# R7FA6E2BB register map
Vendor: Renesas Electronics Corporation; Series: RA6; File version: 1.30.00
CPU: CM33 r0p4, little endian, MPU, FPU, VTOR, 4 interrupt priority bits, 96 interrupts
Registers are 32-bit, read-write, reset 0x0 unless marked. A register's access mark holds for its fields unless they carry their own. Offsets are from the block's base; [hi:lo] are bit positions; 'fields as' and 'values as' point back to an identical list.

## POEG — Port Output Enable Module for GPT
Base 0x4008A000
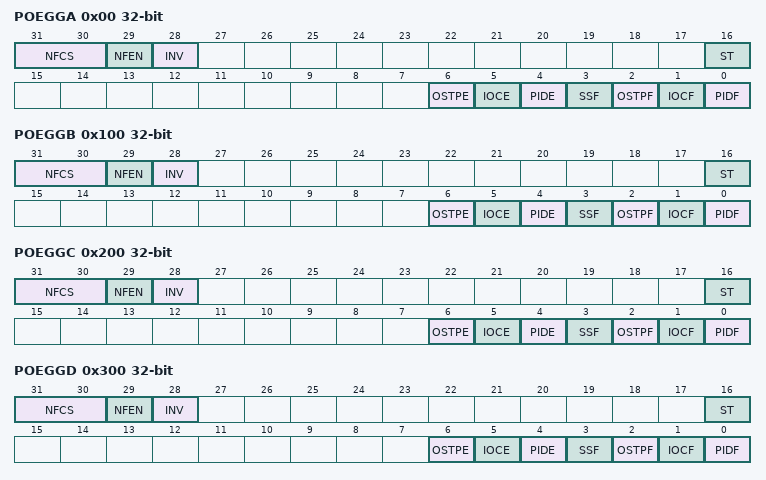
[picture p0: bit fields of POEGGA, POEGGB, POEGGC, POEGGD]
0x00 POEGGA — POEG Group A Setting Register
  [31:30] NFCS — Noise Filter Clock Select
  [29] NFEN — Noise Filter Enable
  [28] INV — GTETRGn Input Reverse
  [16] ST ro — GTETRGn Input Status Flag
  [6] OSTPE — Oscillation Stop Detection Enable
  [5] IOCE — Enable for GPT Output,Disable Request
  [4] PIDE — Port Input Detection Enable
  [3] SSF — Software Stop Flag
  [2] OSTPF — Oscillation Stop Detection Flag
  [1] IOCF — Detection Flag for GPT Output,Disable Request
  [0] PIDF — Port Input Detection Flag
0x100 POEGGB — POEG Group B Setting Register
  fields as POEGGA
0x200 POEGGC — POEG Group C Setting Register
  fields as POEGGA
0x300 POEGGD — POEG Group D Setting Register
  fields as POEGGA

## SSIE0 — Serial Sound Interface Enhanced (SSIE)
Base 0x4009D000
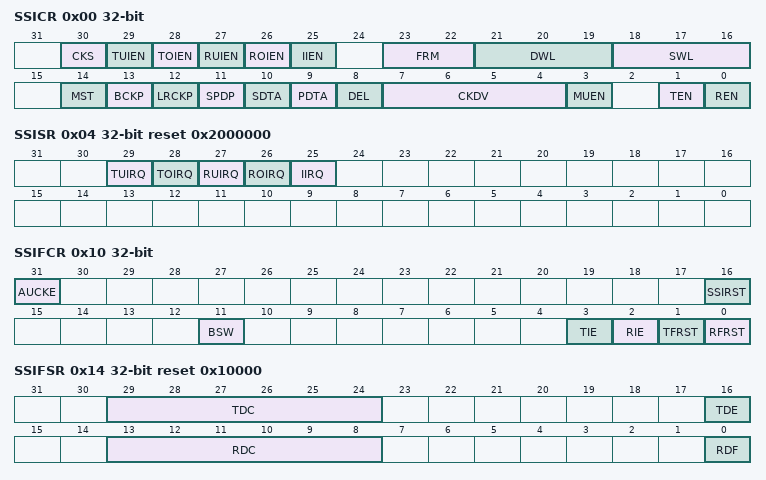
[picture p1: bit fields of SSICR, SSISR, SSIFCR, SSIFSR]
0x00 SSICR — Control Register
  [30] CKS — Selects an Audio Clock for Master,mode Communication
  [29] TUIEN — Transmit Underflow Interrupt Output Enable
  [28] TOIEN — Transmit Overflow Interrupt Output Enable
  [27] RUIEN — Receive Underflow Interrupt Output Enable
  [26] ROIEN — Receive Overflow Interrupt Output Enable
  [25] IIEN — Idle Mode Interrupt Output Enable
  [23:22] FRM — Selects Frame Word Number
  [21:19] DWL — Selects Data Word Length
  [18:16] SWL — Selects System Word Length
  [14] MST — Master Enable
  [13] BCKP — Selects Bit Clock Polarity
  [12] LRCKP — Selects the Initial Value and Polarity of LR Clock/Frame Synchronization Signal
  [11] SPDP — Selects Serial Padding Polarity
  [10] SDTA — Selects Serial Data Alignment
  [9] PDTA — Selects Placement Data Alignment
  [8] DEL — Selects Serial Data Delay
  [7:4] CKDV — Selects Bit Clock Division Ratio
  [3] MUEN — Mute Enable
  [1] TEN — Transmission Enable
  [0] REN — Reception Enable
0x04 SSISR reset 0x2000000 — Status Register
  [29] TUIRQ — Transmit Underflow Error Status flag
  [28] TOIRQ — Transmit Overflow Error Status Flag
  [27] RUIRQ — Receive Underflow Error Status Flag
  [26] ROIRQ — Receive Overflow Error Status Flag
  [25] IIRQ ro — Idle Mode Status Flag
0x10 SSIFCR — FIFO Control Register
  [31] AUCKE — AUDIO_MCK Enable in Master,mode Communication
  [16] SSIRST — Software Reset
  [11] BSW — Byte Swap Enable
  [3] TIE — Transmit Data Empty Interrupt Output Enable
  [2] RIE — Receive Data Full Interrupt Output Enable
  [1] TFRST — Transmit FIFO Data Register Reset
  [0] RFRST — Receive FIFO Data Register Reset
0x14 SSIFSR reset 0x10000 — FIFO Status Register
  [29:24] TDC ro — Transmit Data Count
  [16] TDE — Transmit Data Empty Flag
  [13:8] RDC ro — Receive Data Count
  [0] RDF — Receive Data Full Flag
0x18 SSIFTDR wo — Transmit FIFO Data Register
  [31:0] SSIFTDR — Transmit FIFO Data
0x1C SSIFRDR ro — Receive FIFO Data Register
  [31:0] SSIFRDR — Receive FIFO Data
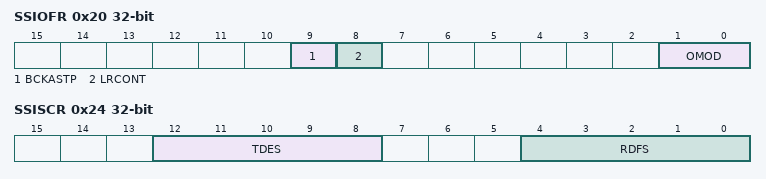
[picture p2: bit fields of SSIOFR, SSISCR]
0x20 SSIOFR — Audio Format Register
  [9] BCKASTP — Whether to Enable Stopping BCK Output When SSIE is in Idle Status
  [8] LRCONT — Whether to Enable LRCK/FS Continuation
  [1:0] OMOD — Audio Format Select
0x24 SSISCR — Status Control Register
  [12:8] TDES — TDE Setting Condition Select
  [4:0] RDFS — RDF Setting Condition Select

## PSCU — Peripheral Security Control Unit
Base 0x400E0000
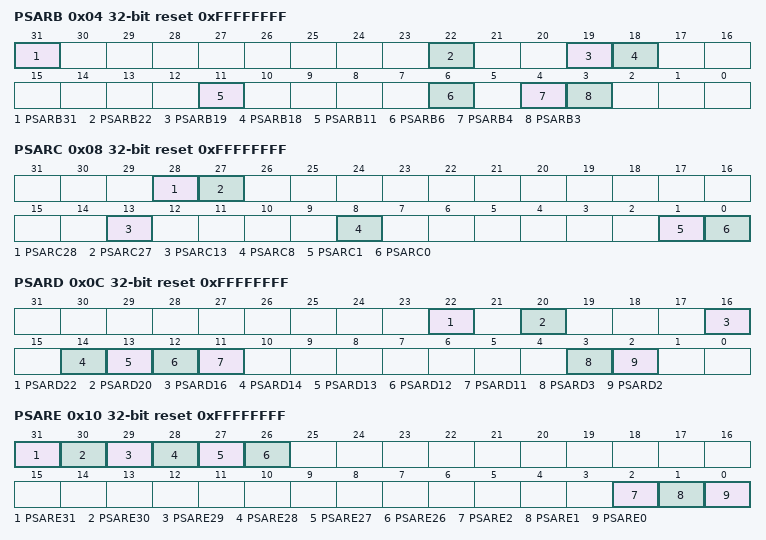
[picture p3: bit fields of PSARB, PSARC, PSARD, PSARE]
0x04 PSARB reset 0xFFFFFFFF — Peripheral Security Attribution Register B
  [31] PSARB31 — SCI0 and the MSTPCRB.MSTPB31 bit security attribution
  [22] PSARB22 — SCI9 and the MSTPCRB.MSTPB22 bit security attribution
  [19] PSARB19 — SPI0 and the MSTPCRB.MSTPB19 bit security attribution
  [18] PSARB18 — SPI1 and the MSTPCRB.MSTPB18 bit security attribution
  [11] PSARB11 — USBFS and the MSTPCRB.MSTPB11 bit security attribution
  [6] PSARB6 ro — QSPI and the MSTPCRB.MSTPB6 bit security attribution
  [4] PSARB4 — I3C and the MSTPCRB.MSTPB4 bit security attribution
  [3] PSARB3 — CEC and the MSTPCRB.MSTPB3 bit security attribution
0x08 PSARC reset 0xFFFFFFFF — Peripheral Security Attribution Register C
  [28] PSARC28 — TRNG and the MSTPCRC.MSTPC28 bit security attribution
  [27] PSARC27 — CANFD0 and the MSTPCRC.MSTPC27 bit security attribution
  [13] PSARC13 — DOC and the MSTPCRC.MSTPC13 bit security attribution
  [8] PSARC8 — SSIE0 and the MSTPCRC.MSTPC8 bit security attribution
  [1] PSARC1 — CRC and the MSTPCRC.MSTPC1 bit security attribution
  [0] PSARC0 — CAC and the MSTPCRC.MSTPC0 bit security attribution
0x0C PSARD reset 0xFFFFFFFF — Peripheral Security Attribution Register D
  [22] PSARD22 — TSN and the MSTPCRD.MSTPD22 bit security attribution
  [20] PSARD20 — DAC12 and the MSTPCRD.MSTPD20 bit security attribution
  [16] PSARD16 — ADC120 and the MSTPCRD.MSTPD16 bit security attribution
  [14] PSARD14 — POEG Group A and the MSTPCRD.MSTPD14 bit security attribution
  [13] PSARD13 — POEG Group B and the MSTPCRD.MSTPD13 bit security attribution
  [12] PSARD12 — POEG Group C and the MSTPCRD.MSTPD12 bit security attribution
  [11] PSARD11 — POEG Group D and the MSTPCRD.MSTPD11 bit security attribution
  [3] PSARD3 — AGT0 and the MSTPCRD.MSTPD3 bit security attribution
  [2] PSARD2 — AGT1 and the MSTPCRD.MSTPD2 bit security attribution
0x10 PSARE reset 0xFFFFFFFF — Peripheral Security Attribution Register E
  [31] PSARE31 — GPT0, GPT_OPS and the MSTPCRE.MSTPE31 bit security attribution
  [30] PSARE30 — GPT1 and the MSTPCRE.MSTPE30 bit security attribution
  [29] PSARE29 — GPT2 and the MSTPCRE.MSTPE29 bit security attribution
  [28] PSARE28 — GPT3 and the MSTPCRE.MSTPE28 bit security attribution
  [27] PSARE27 — GPT4 and the MSTPCRE.MSTPE27 bit security attribution
  [26] PSARE26 — GPT5 and the MSTPCRE.MSTPE26 bit security attribution
  [2] PSARE2 — RTC security attribution
  [1] PSARE1 — IWDT security attribution
  [0] PSARE0 — WDT security attribution
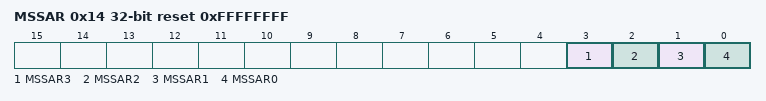
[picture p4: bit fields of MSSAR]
0x14 MSSAR reset 0xFFFFFFFF — Module Stop Security Attribution Register
  [3] MSSAR3 — The MSTPCRA.MSTPA0 bit security attribution
  [2] MSSAR2 — The MSTPCRA.MSTPA7 bit security attribution
  [1] MSSAR1 — The MSTPCRA.MSTPA22 bit security attribution
  [0] MSSAR0 — The MSTPCRC.MSTPC14 bit security attribution
0x18 CFSAMONA (reset mask 0xFF007FFF) — Code Flash Security Attribution Register A
  [23:15] CFS2 — Code Flash Secure area 2
0x1C CFSAMONB (reset mask 0xFF0003FF) — Code Flash Security Attribution Register B
  [23:10] CFS1 — Code Flash Secure area 1
0x20 DFSAMON reset 0xFC00 — Data Flash Security Attribution Register
  [15:10] DFS — Data flash Secure area
0x24 SSAMONA reset 0x1FE000 — SRAM Security Attribution Register A
  [20:13] SS2 — SRAM Secure area 2
0x28 SSAMONB reset 0x1FFC00 — SRAM Security Attribution Register B
  [20:10] SS1 — SRAM secure area 1
